# BlueNRG_LP register map
File version: 1.0
CPU: CM0+ r0p0, little endian, no MPU, no FPU, 2 interrupt priority bits
Registers are 32-bit, read-write, reset 0x0 unless marked. A register's access mark holds for its fields unless they carry their own. Offsets are from the block's base; [hi:lo] are bit positions.

## RCC — Reset and clock control
Base 0x48400000
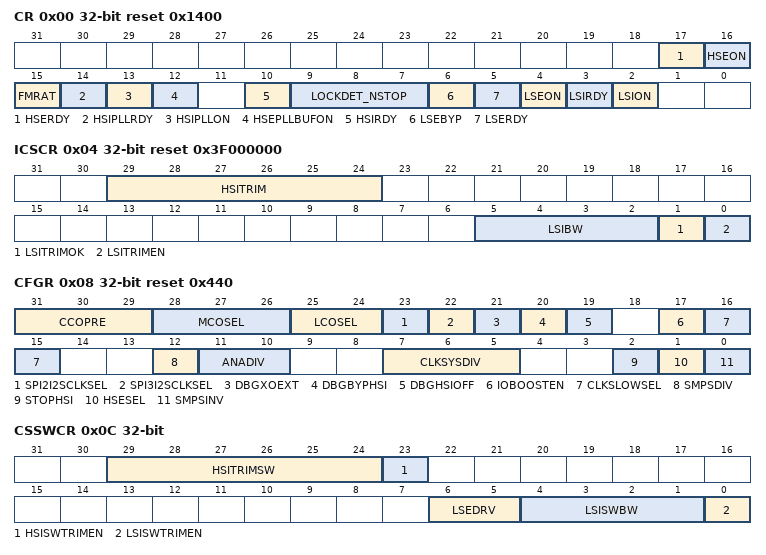
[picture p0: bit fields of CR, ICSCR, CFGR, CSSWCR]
0x00 CR reset 0x1400 — Clock control register
  [17] HSERDY ro — External High Speed clock flag.
  [16] HSEON — External High Speed clock enable.
  [15] FMRAT
  [14] HSIPLLRDY — Internal High Speed clock PLL flag. This bit is set by hardware to indicate that the RC64MPLL pll is locked
  [13] HSIPLLON — Internal High Speed clock PLL enable
  [12] HSEPLLBUFON — External high speed clock buffer for PLL RF2G4 enable.
  [10] HSIRDY ro — HSI clock ready flag
  [9:7] LOCKDET_NSTOP
  [6] LSEBYP — External Low Speed clock bypass.
  [5] LSERDY ro — External Low Speed clock flag
  [4] LSEON — External Low Speed clock enable
  [3] LSIRDY ro — Internal Low Speed clock flag
  [2] LSION — Internal low speed RC clock enable
0x04 ICSCR reset 0x3F000000 — Internal clock sources calibration register
  [29:24] HSITRIM ro — High speed clock trimming.
  [5:2] LSIBW ro — Low speed clock trimming.
  [1] LSITRIMOK ro — Low speed internal RC trimming value is OK.
  [0] LSITRIMEN — Low speed internal RC trimming enable.
0x08 CFGR reset 0x440 — Clock configuration register
  [31:29] CCOPRE — Configurable Clock Output Prescaler
  [28:26] MCOSEL — Microcontroller clock output
  [25:24] LCOSEL — Low speed Configurable Clock Output Selection
  [23] SPI2I2SCLKSEL — Selection of I2S clock for SPI3 IP
  [22] SPI3I2SCLKSEL — Selection of I2S clock for SPI2 IP
  [21] DBGXOEXT — Used for debug mode only
  [20] DBGBYPHSI — Used for debug mode only
  [19] DBGHSIOFF — Used for debug mode only
  [17] IOBOOSTEN — IO BOOSTER external clock enable
  [16:15] CLKSLOWSEL — low speed clock source selection
  [12] SMPSDIV — SMPS clock prescaling factor
  [11:10] ANADIV — SMPS and ADC clock prescaling factor
  [7:5] CLKSYSDIV — system clock divided factor from HSI_64M
  [2] STOPHSI — RC64MPLL clock source stop request
  [1] HSESEL — Clock source selection request.
  [0] SMPSINV — control inversion of SMPS clock, versus ADC clock
0x0C CSSWCR — Clocks Sources Software Calibration register
  [29:24] HSITRIMSW — High speed clock trimming set by software
  [23] HSISWTRIMEN — High speed clock software trimming enable
  [6:5] LSEDRV — external 32 kHz crystal GM
  [4:1] LSISWBW — Low speed internal RC trimming value set by software
  [0] LSISWTRIMEN — Low speed internal RC software trimming enable
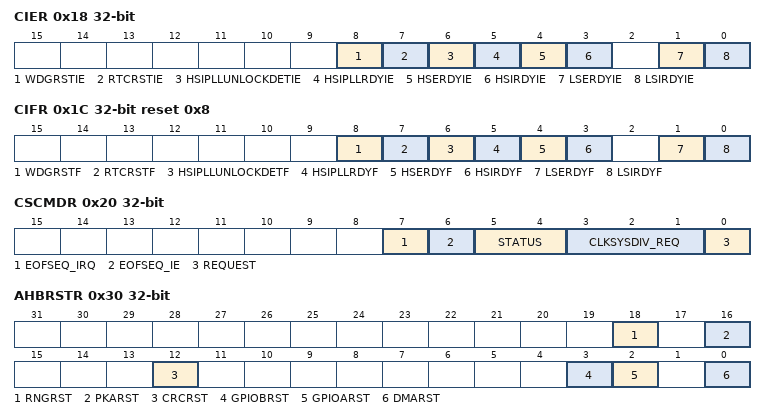
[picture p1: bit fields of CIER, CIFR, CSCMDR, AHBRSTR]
0x18 CIER — Clock interrupt enable register
  [8] WDGRSTIE — Watchdog reset release interrupt enable.
  [7] RTCRSTIE — RTC reset release interrupt enable.
  [6] HSIPLLUNLOCKDETIE — HSI PLL unlock detection interrupt enable.
  [5] HSIPLLRDYIE — HSI PLLSYS ready interrupt enable
  [4] HSERDYIE — HSE ready interrupt enable
  [3] HSIRDYIE — HSI ready interrupt enable
  [1] LSERDYIE — LSE ready interrupt enable
  [0] LSIRDYIE — LSI1 ready interrupt enable
0x1C CIFR reset 0x8 — Clock interrupt flag register
  [8] WDGRSTF — Watchdog reset release flag.
  [7] RTCRSTF — RTC reset release flag.
  [6] HSIPLLUNLOCKDETF — HSI PLL unlock detection flag.
  [5] HSIPLLRDYF — HSI PLL ready flag
  [4] HSERDYF — HSE ready interrupt flag
  [3] HSIRDYF — HSI ready interrupt flag
  [1] LSERDYF — LSE ready interrupt flag
  [0] LSIRDYF — LSI1 ready interrupt flag
0x20 CSCMDR — This register allows switching the CPU system clock frequency safely while the MR_BLE is active.
  [7] EOFSEQ_IRQ — End of sequence flag.
  [6] EOFSEQ_IE — End of sequence interrupt enable.
  [5:4] STATUS — Status of the switching sequence.
  [3:1] CLKSYSDIV_REQ — System clock requested/targeted frequency.
  [0] REQUEST — Request to switch the system clock frequency.
0x30 AHBRSTR — AHB0 macro cells reset register
  [18] RNGRST — RNG reset
  [16] PKARST — PKA reset
  [12] CRCRST — CRC reset
  [3] GPIOBRST — IO controller for port A reset
  [2] GPIOARST — IO controller for port B reset
  [0] DMARST — DMA and DMAMUX reset
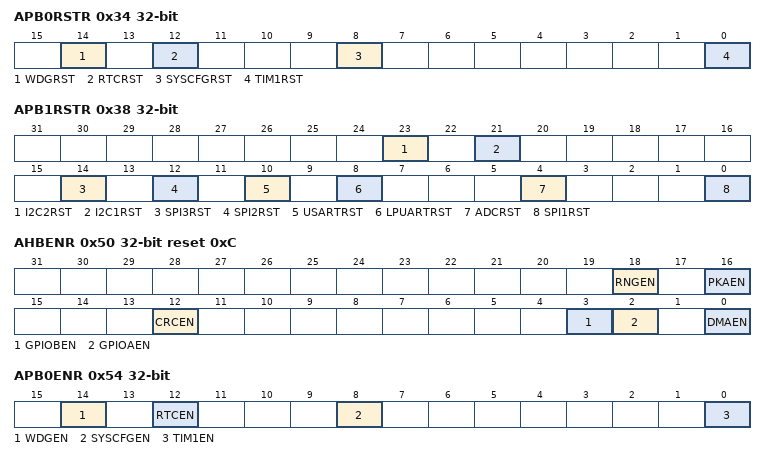
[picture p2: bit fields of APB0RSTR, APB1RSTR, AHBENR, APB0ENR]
0x34 APB0RSTR — APB0 macro cells reset register
  [14] WDGRST — Watchdog reset
  [12] RTCRST — RTC reset
  [8] SYSCFGRST — system controller reset
  [0] TIM1RST — TIM1 reset
0x38 APB1RSTR — APB1 peripheral reset register 1
  [23] I2C2RST — I2C2 reset
  [21] I2C1RST — I2C1 reset
  [14] SPI3RST — SPI3 reset
  [12] SPI2RST — SPI2 reset
  [10] USARTRST — USARTRST: USART reset
  [8] LPUARTRST — LPUART reset
  [4] ADCRST — ADC reset
  [0] SPI1RST — SPI1 reset
0x40 APB2RSTR — APB2 peripheral reset register 2
  [0] MRBLERST — MR_BLE Bluetooth radio reset
0x50 AHBENR reset 0xC — AHB0 macro cells clock enable register
  [18] RNGEN — RNG clock enable
  [16] PKAEN — PKAEN: PKA enable
  [12] CRCEN — CRCEN: CRC enable
  [3] GPIOBEN — IO controller for port B enable
  [2] GPIOAEN — IO controller for port A enable
  [0] DMAEN — DMA and DMAMUX enable
0x54 APB0ENR — APB0 macro cells clock enable register
  [14] WDGEN — Watchdog enable.
  [12] RTCEN — RTC enable.
  [8] SYSCFGEN — system controller enable.
  [0] TIM1EN — TIM1 enable.
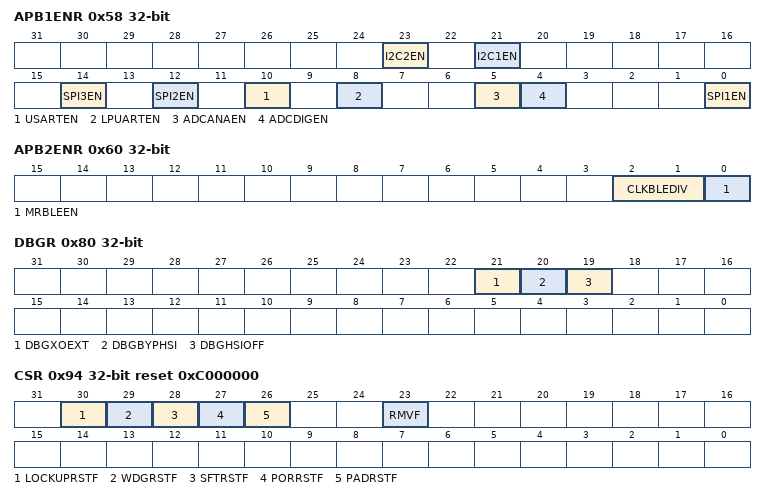
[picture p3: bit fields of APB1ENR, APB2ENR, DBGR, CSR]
0x58 APB1ENR
  [23] I2C2EN — I2C2 enable
  [21] I2C1EN — CPU1 I2C1 clock enable
  [14] SPI3EN — CPU1 SPI3 clock enable
  [12] SPI2EN — SPI2 enable
  [10] USARTEN — USART enable
  [8] LPUARTEN — LPUART enable
  [5] ADCANAEN
  [4] ADCDIGEN
  [0] SPI1EN — SPI1 enable
0x60 APB2ENR
  [2:1] CLKBLEDIV — MR_BLE (Bluetooth Low Energy radio) clock frequency selection when RCC_APB2ENR.MRBLEEN=1.
  [0] MRBLEEN — MR_BLE (Bluetooth radio) enable.
0x80 DBGR — This register is planned for debug use-case only.
  [21] DBGXOEXT — Used for debug mode only.
  [20] DBGBYPHSI — Used for debug mode only.
  [19] DBGHSIOFF — Used for debug mode only.
0x94 CSR reset 0xC000000
  [30] LOCKUPRSTF ro — CPU lockup reset flag
  [29] WDGRSTF ro — Watchdog reset flag
  [28] SFTRSTF ro — Software reset flag
  [27] PORRSTF ro — Power-On reset flag
  [26] PADRSTF ro — NRSTn pad reset flag.
  [23] RMVF — Remove Flag reset
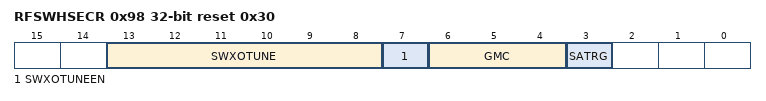
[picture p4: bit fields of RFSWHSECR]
0x98 RFSWHSECR reset 0x30 — RF Software High Speed External register
  [13:8] SWXOTUNE — RF HSE capacitor bank tuning value set by software
  [7] SWXOTUNEEN — RF HSE software capacitor bank tuning enable
  [6:4] GMC — High speed external IO current control
  [3] SATRG — Sense Amplifier Threshold
0x9C RFHSECR ro — RF High Speed External register
  [5:0] XOTUNE — RF-HSE capacitor bank tuning
